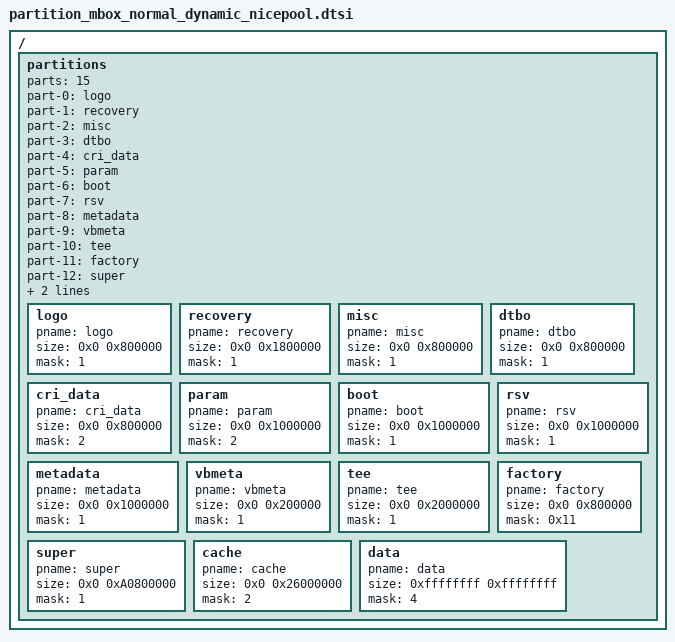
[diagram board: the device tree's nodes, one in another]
/*
 * Amlogic partition set for normal
 *
 * Copyright (c) 2017-2017 Amlogic Ltd
 *
 * This file is licensed under a dual GPLv2 or BSD license.
 *
 */

#include "firmware_avb_deadpool.dtsi"

/ {
    partitions: partitions{
		parts = <15>;
		part-0 = <&logo>;
		part-1 = <&recovery>;
		part-2 = <&misc>;
		part-3 = <&dtbo>;
		part-4 = <&cri_data>;
		part-5 = <&param>;
		part-6 = <&boot>;
		part-7 = <&rsv>;
		part-8 = <&metadata>;
		part-9 = <&vbmeta>;
		part-10 = <&tee>;
		part-11 = <&factory>;
		part-12 = <&super>;
		part-13 = <&cache>;
		part-14 = <&data>;

		logo:logo{
			pname = "logo";
			size = <0x0 0x800000>;
			mask = <1>;
		};
		recovery:recovery{
			pname = "recovery";
			size = <0x0 0x1800000>;
			mask = <1>;
		};
		misc:misc{
			pname = "misc";
			size = <0x0 0x800000>;
			mask = <1>;
		};
		dtbo:dtbo{
			pname = "dtbo";
			size = <0x0 0x800000>;
			mask = <1>;
		};
		cri_data:cri_data
		{
			pname = "cri_data";
			size = <0x0 0x800000>;
			mask = <2>;
		};
		param:param{
			pname = "param";
			size = <0x0 0x1000000>;
			mask = <2>;
		};
		boot:boot
		{
			pname = "boot";
			size = <0x0 0x1000000>;
			mask = <1>;
		};
		rsv:rsv{
			pname = "rsv";
			size = <0x0 0x1000000>;
			mask = <1>;
		};
		metadata:metadata{
			pname = "metadata";
			size = <0x0 0x1000000>;
			mask = <1>;
		};
		vbmeta:vbmeta{
			pname = "vbmeta";
			size = <0x0 0x200000>;
			mask = <1>;
		};
		tee:tee{
			pname = "tee";
			size = <0x0 0x2000000>;
			mask = <1>;
		};
		factory:factory{
			pname = "factory";
			size = <0x0 0x800000>;
			mask = <0x11>;
		};
		super:super
		{
			pname = "super";
			size = <0x0 0xA0800000>;
			mask = <1>;
		};
		cache:cache
		{
			pname = "cache";
			size = <0x0 0x26000000>;
			mask = <2>;
		};
		data:data
		{
			pname = "data";
			size = <0xffffffff 0xffffffff>;
			mask = <4>;
		};
	};
};/* end of / */
